VERSION ""

NS_ :

BS_:

BU_: VCL HSC BCM

BO_ 3221225472 VECTOR__INDEPENDENT_SIG_MSG: 0 Vector__XXX
 SG_ Faults : 0|32@1- (1,0) [0|0] "" Vector__XXX

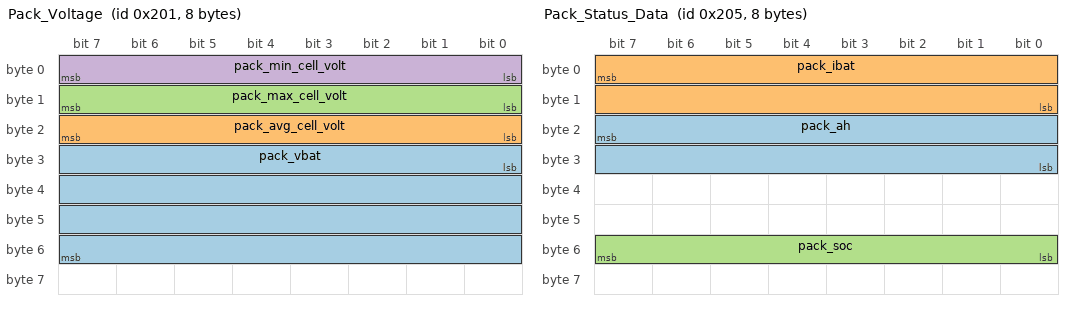
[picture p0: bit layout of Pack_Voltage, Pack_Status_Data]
BO_ 513 Pack_Voltage: 8 Vector__XXX
 SG_ pack_vbat : 24|32@1- (0.01,0) [0|1000] "v" Vector__XXX
 SG_ pack_avg_cell_volt : 16|8@1- (0.01,2) [0|0] "v" Vector__XXX
 SG_ pack_max_cell_volt : 8|8@1- (0.01,2) [0|0] "v" Vector__XXX
 SG_ pack_min_cell_volt : 0|8@1- (0.01,2) [0|0] "v" Vector__XXX

BO_ 517 Pack_Status_Data: 8 Vector__XXX
 SG_ pack_ah : 23|16@0- (0.1,0) [0|0] "Ah" Vector__XXX
 SG_ pack_ibat : 7|16@0- (0.1,1) [-500|125] "A" Vector__XXX
 SG_ pack_soc : 48|8@1+ (1,0) [0|100] "%" Vector__XXX

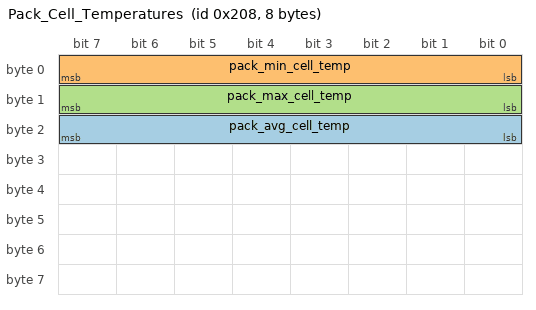
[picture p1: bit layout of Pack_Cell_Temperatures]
BO_ 520 Pack_Cell_Temperatures: 8 Vector__XXX
 SG_ pack_avg_cell_temp : 16|8@1- (1,-100) [0|0] "C" Vector__XXX
 SG_ pack_min_cell_temp : 0|8@1- (1,-100) [0|0] "C" Vector__XXX
 SG_ pack_max_cell_temp : 8|8@1- (1,-100) [0|0] "C" Vector__XXX

CM_ BO_ 3221225472 "This is a message for not used signals, created by Vector CANdb++ DBC OLE DB Provider.";
BA_DEF_  "BusType" STRING ;
BA_DEF_DEF_  "BusType" "";
BA_ "BusType" "CAN";
